# CM32M4xxR register map
Vendor: CMIOT XinSheng Tech Ltd.; File version: 2.0
Registers are 32-bit, read-write, reset 0x0 unless marked. A register's access mark holds for its fields unless they carry their own. Offsets are from the block's base; [hi:lo] are bit positions; {n}, {i} and the like mark numbered series; 'fields as' and 'values as' point back to an identical list.

## CAN1 — Controller area network
Base 0x40006400
Same registers: CAN2 0x40006800
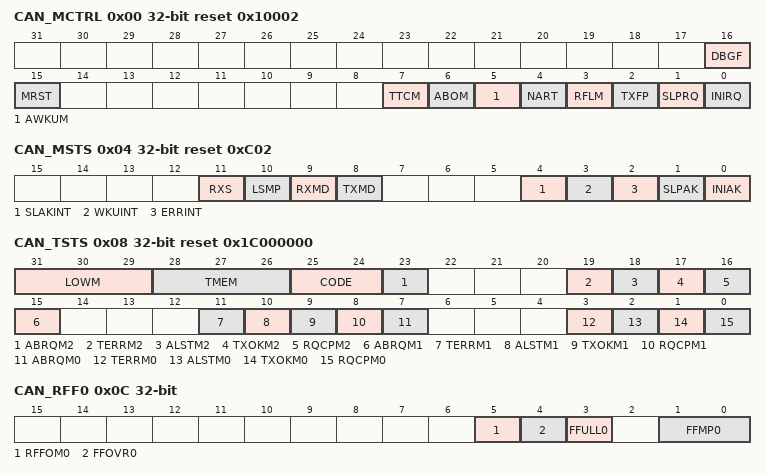
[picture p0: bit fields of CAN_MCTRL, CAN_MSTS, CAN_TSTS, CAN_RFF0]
0x00 CAN_MCTRL reset 0x10002
  [16] DBGF, [15] MRST, [7] TTCM, [6] ABOM, [5] AWKUM, [4] NART, [3] RFLM, [2] TXFP, [1] SLPRQ, [0] INIRQ
0x04 CAN_MSTS reset 0xC02
  [11] RXS, [10] LSMP, [9] RXMD, [8] TXMD, [4] SLAKINT, [3] WKUINT, [2] ERRINT, [1] SLPAK, [0] INIAK
0x08 CAN_TSTS reset 0x1C000000
  [31:29] LOWM, [28:26] TMEM, [25:24] CODE, [23] ABRQM2, [19] TERRM2, [18] ALSTM2, [17] TXOKM2, [16] RQCPM2, [15] ABRQM1, [11] TERRM1, [10] ALSTM1, [9] TXOKM1, [8] RQCPM1, [7] ABRQM0, [3] TERRM0, [2] ALSTM0, [1] TXOKM0, [0] RQCPM0
0x0C CAN_RFF0
  [5] RFFOM0, [4] FFOVR0, [3] FFULL0, [1:0] FFMP0
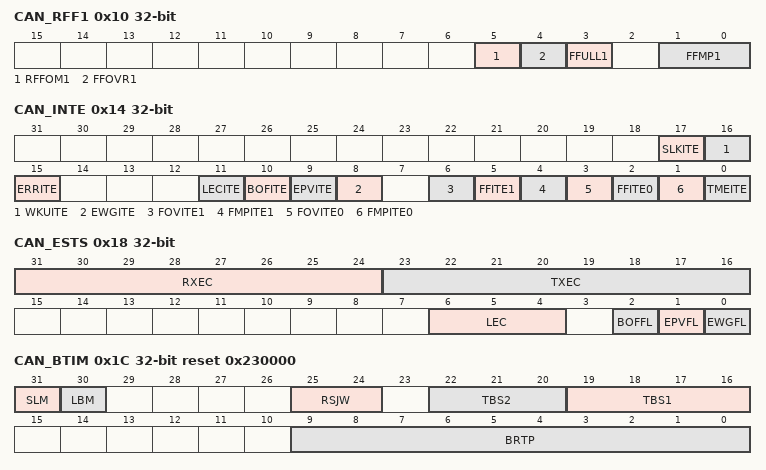
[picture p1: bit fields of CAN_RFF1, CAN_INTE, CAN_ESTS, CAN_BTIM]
0x10 CAN_RFF1
  [5] RFFOM1, [4] FFOVR1, [3] FFULL1, [1:0] FFMP1
0x14 CAN_INTE
  [17] SLKITE, [16] WKUITE, [15] ERRITE, [11] LECITE, [10] BOFITE, [9] EPVITE, [8] EWGITE, [6] FOVITE1, [5] FFITE1, [4] FMPITE1, [3] FOVITE0, [2] FFITE0, [1] FMPITE0, [0] TMEITE
0x18 CAN_ESTS
  [31:24] RXEC, [23:16] TXEC, [6:4] LEC, [2] BOFFL, [1] EPVFL, [0] EWGFL
0x1C CAN_BTIM reset 0x230000
  [31] SLM, [30] LBM, [25:24] RSJW, [22:20] TBS2, [19:16] TBS1, [9:0] BRTP
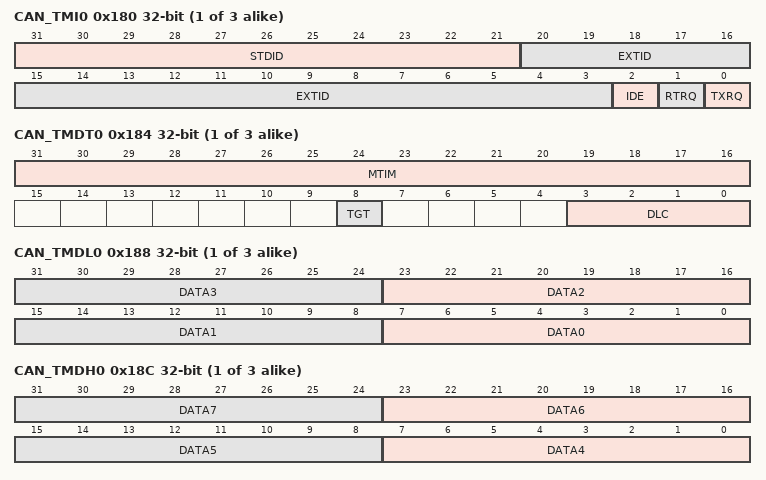
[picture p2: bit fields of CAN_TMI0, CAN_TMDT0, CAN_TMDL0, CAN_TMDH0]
{0x180+0x10*i} CAN_TMI{i} (i=0..2)
  [31:21] STDID, [20:3] EXTID, [2] IDE, [1] RTRQ, [0] TXRQ
{0x184+0x10*i} CAN_TMDT{i} (i=0..2)
  [31:16] MTIM, [8] TGT, [3:0] DLC
{0x188+0x10*i} CAN_TMDL{i} (i=0..2)
  [8n+7:8n] DATA{n} (n=0..3)
{0x18C+0x10*i} CAN_TMDH{i} (i=0..2)
  [8n-25:8n-32] DATA{n} (n=4..7)
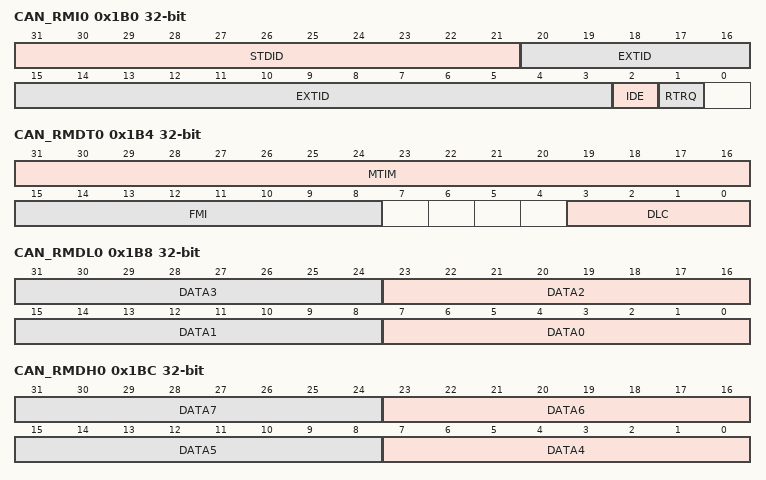
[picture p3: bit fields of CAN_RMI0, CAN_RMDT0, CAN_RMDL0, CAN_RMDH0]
0x1B0 CAN_RMI0
  [31:21] STDID, [20:3] EXTID, [2] IDE, [1] RTRQ
0x1B4 CAN_RMDT0
  [31:16] MTIM, [15:8] FMI, [3:0] DLC
0x1B8 CAN_RMDL0
  [8n+7:8n] DATA{n} (n=0..3)
0x1BC CAN_RMDH0
  [8n-25:8n-32] DATA{n} (n=4..7)
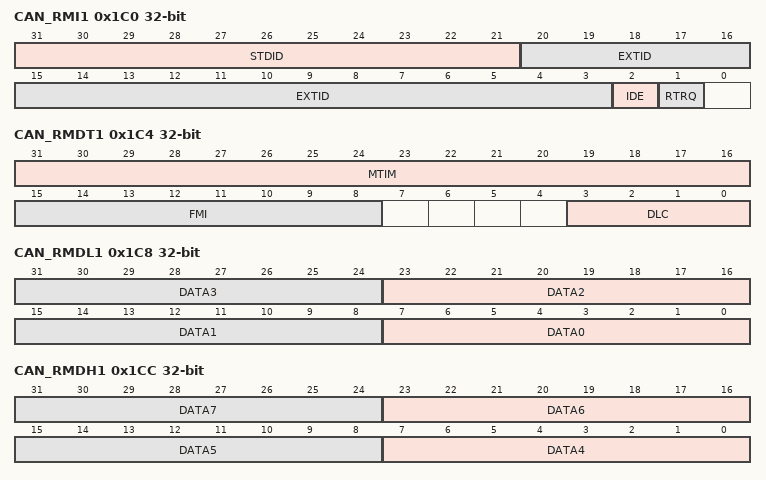
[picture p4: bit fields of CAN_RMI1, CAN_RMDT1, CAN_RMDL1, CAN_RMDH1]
0x1C0 CAN_RMI1
  [31:21] STDID, [20:3] EXTID, [2] IDE, [1] RTRQ
0x1C4 CAN_RMDT1
  [31:16] MTIM, [15:8] FMI, [3:0] DLC
0x1C8 CAN_RMDL1
  [8n+7:8n] DATA{n} (n=0..3)
0x1CC CAN_RMDH1
  [8n-25:8n-32] DATA{n} (n=4..7)
0x200 CAN_FMC reset 0x1
  [0] FINITM
0x204 CAN_FM1
  [13:0] FB
0x20C CAN_FS1
  [13:0] FSC
0x214 CAN_FFA1
  [13:0] FAF
0x21C CAN_FA1
  [13:0] FAC
0x240 CAN_F0B1
  [31:0] FBC
0x244 CAN_F0B2
  [31:0] FBC
0x248 CAN_F1B1
  [31:0] FBC
0x24C CAN_F1B2
  [31:0] FBC
0x2A8 CAN_F13B1
  [31:0] FBC
0x2AC CAN_F13B2
  [31:0] FBC

## CRC — cyclic redundancy check
Base 0x40023000
0x00 CRC32DAT reset 0xFFFFFFFF
0x04 CRC32IDAT
  [7:0] CRC32IDAT
0x08 CRC32CTRL
  [0] RESET
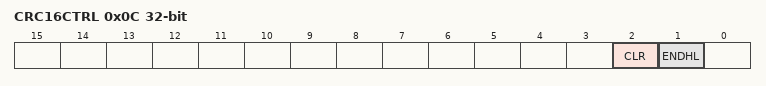
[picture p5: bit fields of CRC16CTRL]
0x0C CRC16CTRL
  [2] CLR, [1] ENDHL
0x10 CRC16DAT
  [7:0] CRC16DAT
0x14 CRC16D
  [15:0] CRC16D
0x18 LRC
  [7:0] LRCDAT

## DAC — digital to analog converter
Base 0x40007400
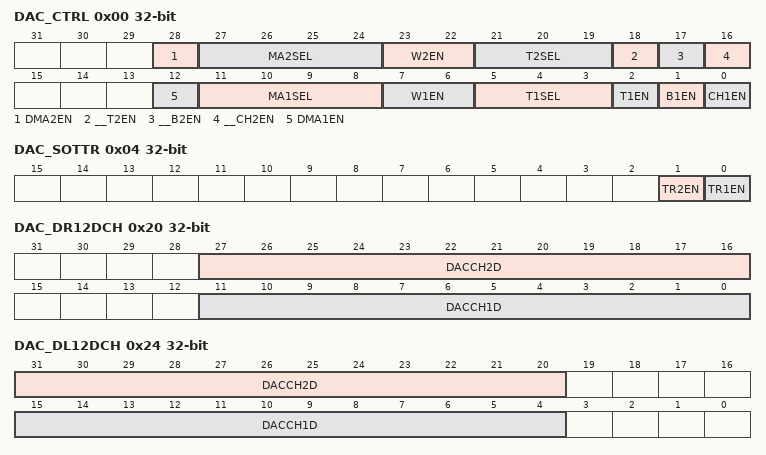
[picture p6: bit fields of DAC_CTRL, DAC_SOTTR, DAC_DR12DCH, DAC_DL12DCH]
0x00 DAC_CTRL
  [28] DMA2EN, [27:24] MA2SEL, [23:22] W2EN, [21:19] T2SEL, [18] __T2EN, [17] __B2EN, [16] __CH2EN, [12] DMA1EN, [11:8] MA1SEL, [7:6] W1EN, [5:3] T1SEL, [2] T1EN, [1] B1EN, [0] CH1EN
0x04 DAC_SOTTR
  [1] TR2EN, [0] TR1EN
0x08 DAC_DR12CH1
  [11:0] DACCH1D
0x0C DAC_DL12CH1
  [15:4] DACCH1D
0x10 DAC_DR8CH1
  [7:0] DACCH1D
0x14 DAC_DR12CH2
  [11:0] DACCH2D
0x18 DAC_DL12CH2
  [15:4] DACCH2D
0x1C DAC_DR8CH2
  [7:0] DACCH2D
0x20 DAC_DR12DCH
  [27:16] DACCH2D, [11:0] DACCH1D
0x24 DAC_DL12DCH
  [31:20] DACCH2D, [15:4] DACCH1D
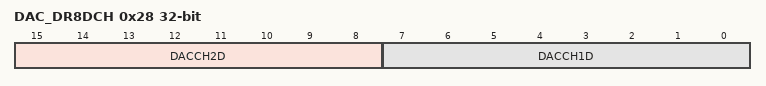
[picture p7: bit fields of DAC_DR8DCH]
0x28 DAC_DR8DCH
  [15:8] DACCH2D, [7:0] DACCH1D
0x2C DAC_DATO1
  [11:0] DACCH1DO
0x30 DAC_DATO2
  [11:0] DACCH2DO

## DBG — debug support for MCU
Base 0xE0040000
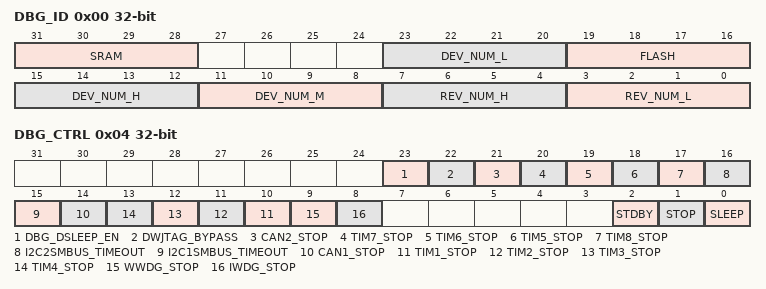
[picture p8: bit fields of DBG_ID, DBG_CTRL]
0x00 DBG_ID
  [31:28] SRAM, [23:20] DEV_NUM_L, [19:16] FLASH, [15:12] DEV_NUM_H, [11:8] DEV_NUM_M, [7:4] REV_NUM_H, [3:0] REV_NUM_L
0x04 DBG_CTRL (reset mask 0x1FFF87)
  [23] DBG_DSLEEP_EN, [22] DWJTAG_BYPASS, [21] CAN2_STOP, [20] TIM7_STOP, [19] TIM6_STOP, [18] TIM5_STOP, [17] TIM8_STOP, [16] I2C2SMBUS_TIMEOUT, [15] I2C1SMBUS_TIMEOUT, [14] CAN1_STOP, [n+9] TIM{n}_STOP (n=1..4), [9] WWDG_STOP, [8] IWDG_STOP, [2] STDBY, [1] STOP, [0] SLEEP

## DMA1 — Direct memory access controller
Base 0x40020000
Same registers: DMA2 0x40020400
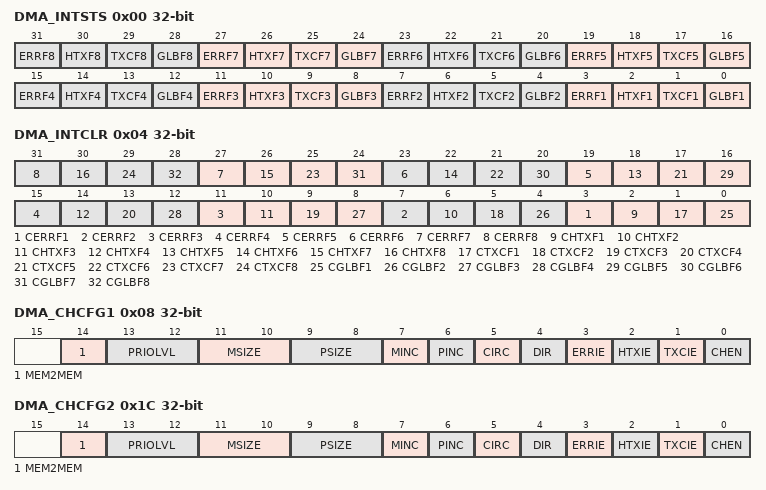
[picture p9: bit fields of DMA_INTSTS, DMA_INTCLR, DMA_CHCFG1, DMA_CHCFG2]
0x00 DMA_INTSTS
  [4n-1] ERRF{n} (n=1..8), [4n-2] HTXF{n} (n=1..8), [4n-3] TXCF{n} (n=1..8), [4n-4] GLBF{n} (n=1..8)
0x04 DMA_INTCLR
  [4n-1] CERRF{n} (n=1..8), [4n-2] CHTXF{n} (n=1..8), [4n-3] CTXCF{n} (n=1..8), [4n-4] CGLBF{n} (n=1..8)
0x08 DMA_CHCFG1
  [14] MEM2MEM, [13:12] PRIOLVL, [11:10] MSIZE, [9:8] PSIZE, [7] MINC, [6] PINC, [5] CIRC, [4] DIR, [3] ERRIE, [2] HTXIE, [1] TXCIE, [0] CHEN
0x0C DMA_TXNUM1
  [15:0] NDTX
0x10 DMA_PADDR1
  [31:0] ADDR
{0x0+0x14*i} DMA_MADDR{i} (i=1..8)
  [31:0] ADDR
{0x4+0x14*i} DMA_CHSEL{i} (i=1..8)
  [5:0] CH_SEL
0x1C DMA_CHCFG2
  fields as DMA_CHCFG1
0x20 DMA_TXNUM2
  [15:0] NDTX
0x24 DMA_PADDR2
  [31:0] ADDR
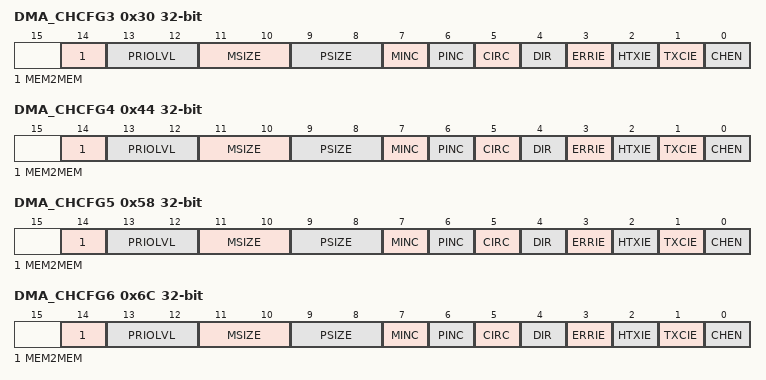
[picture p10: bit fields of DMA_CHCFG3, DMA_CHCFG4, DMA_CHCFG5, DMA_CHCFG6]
0x30 DMA_CHCFG3
  fields as DMA_CHCFG1
0x34 DMA_TXNUM3
  [15:0] NDTX
0x38 DMA_PADDR3
  [31:0] ADDR
0x44 DMA_CHCFG4
  fields as DMA_CHCFG1
0x48 DMA_TXNUM4
  [15:0] NDTX
0x4C DMA_PADDR4
  [31:0] ADDR
0x58 DMA_CHCFG5
  fields as DMA_CHCFG1
0x5C DMA_TXNUM5
  [15:0] NDTX
0x60 DMA_PADDR5
  [31:0] ADDR
0x6C DMA_CHCFG6
  fields as DMA_CHCFG1
0x70 DMA_TXNUM6
  [15:0] NDTX
0x74 DMA_PADDR6
  [31:0] ADDR
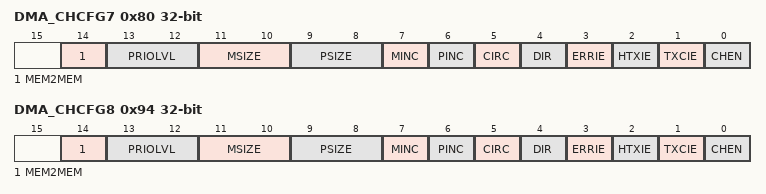
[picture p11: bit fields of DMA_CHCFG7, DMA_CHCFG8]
0x80 DMA_CHCFG7
  fields as DMA_CHCFG1
0x84 DMA_TXNUM7
  [15:0] NDTX
0x88 DMA_PADDR7
  [31:0] ADDR
0x94 DMA_CHCFG8
  fields as DMA_CHCFG1
0x98 DMA_TXNUM8
  [15:0] NDTX
0x9C DMA_PADDR8
  [31:0] ADDR
0xA8 DMA_CHMAPEN
  [0] MAP_EN
